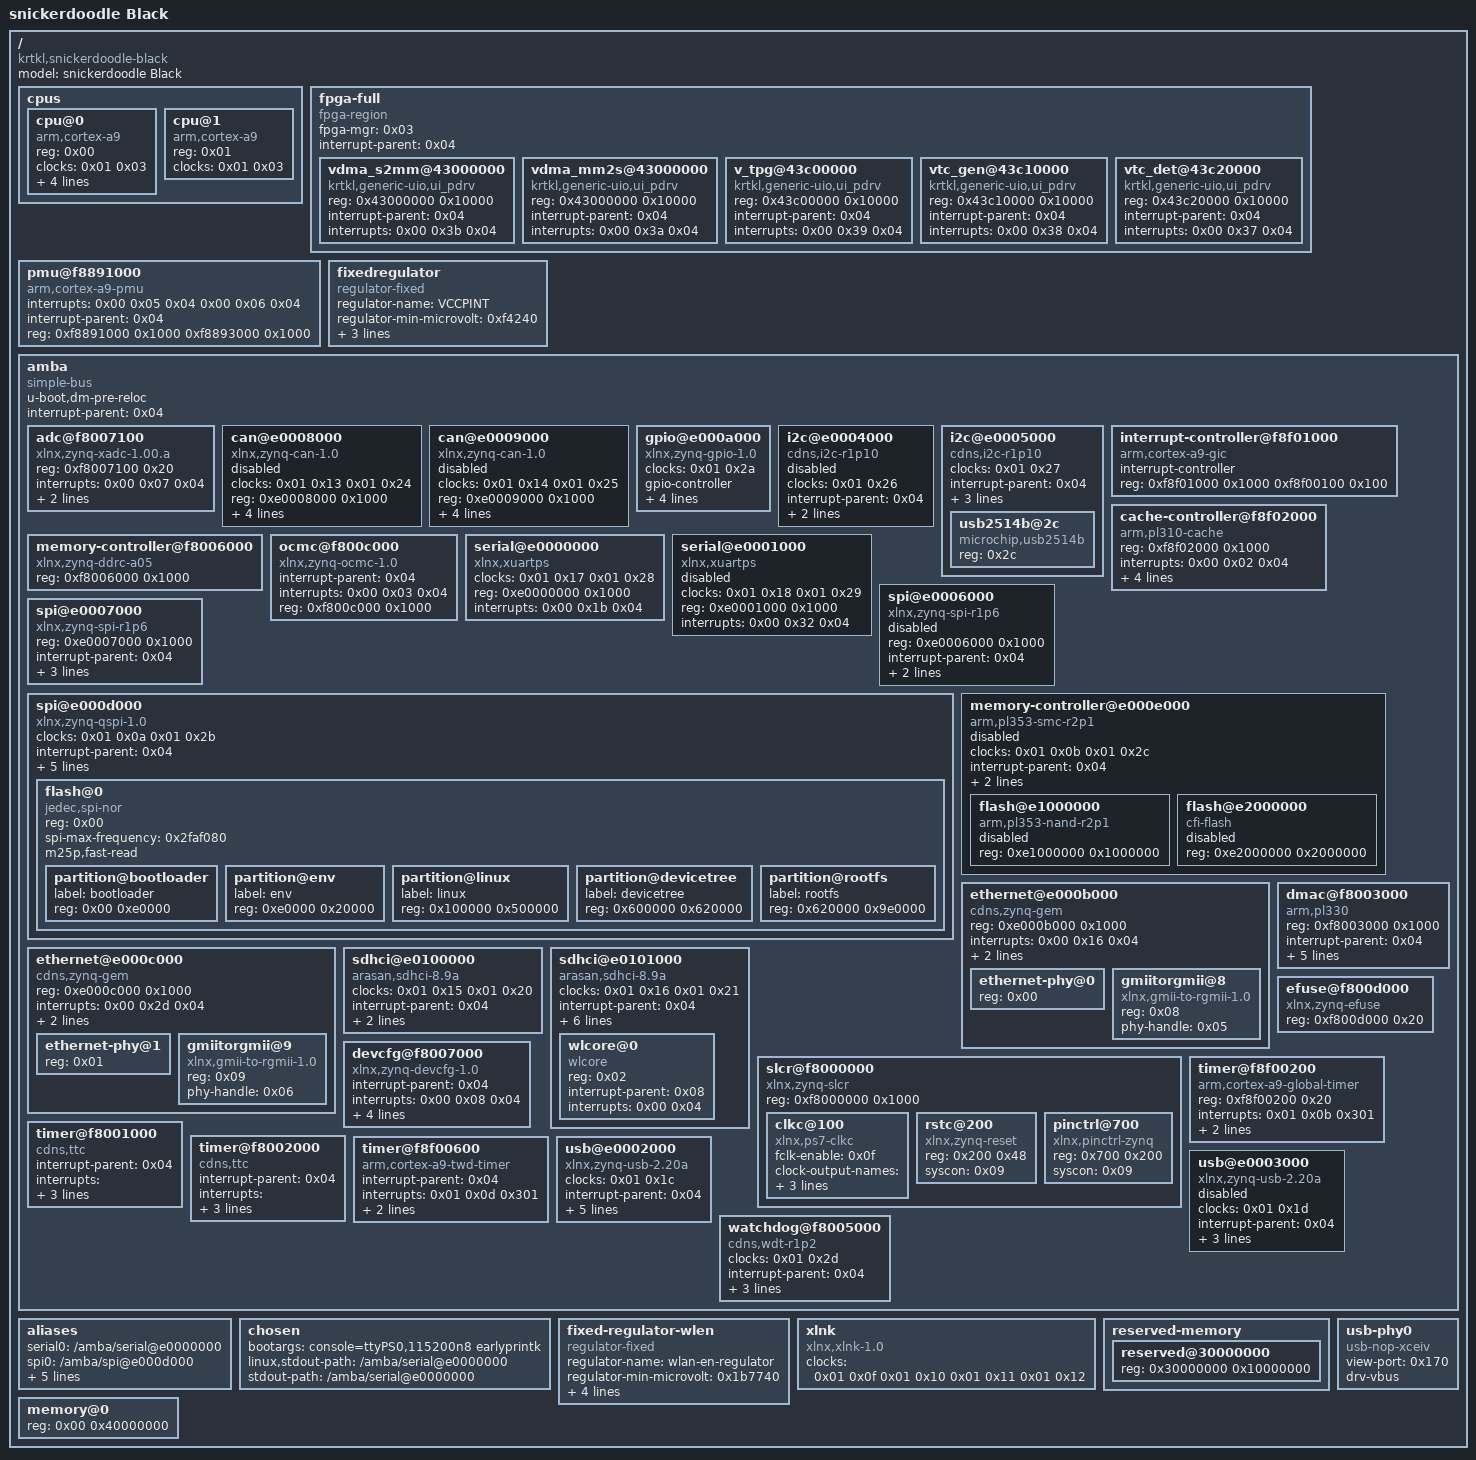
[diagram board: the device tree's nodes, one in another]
/dts-v1/;

/ {
	#address-cells = <0x01>;
	#size-cells = <0x01>;
	compatible = "krtkl,snickerdoodle-black\0krtkl,snickerdoodle\0xlnx,zynq-7000";
	model = "snickerdoodle Black";

	cpus {
		#address-cells = <0x01>;
		#size-cells = <0x00>;

		cpu@0 {
			compatible = "arm,cortex-a9";
			device_type = "cpu";
			reg = <0x00>;
			clocks = <0x01 0x03>;
			clock-latency = <0x3e8>;
			cpu0-supply = <0x02>;
			operating-points = <0xd396a 0xf4240 0x69cb5 0xf4240>;
			linux,phandle = <0x0b>;
			phandle = <0x0b>;
		};

		cpu@1 {
			compatible = "arm,cortex-a9";
			device_type = "cpu";
			reg = <0x01>;
			clocks = <0x01 0x03>;
			linux,phandle = <0x0c>;
			phandle = <0x0c>;
		};
	};

	fpga-full {
		compatible = "fpga-region";
		fpga-mgr = <0x03>;
		#address-cells = <0x01>;
		#size-cells = <0x01>;
		ranges;
		interrupt-parent = <0x04>;
		linux,phandle = <0x0d>;
		phandle = <0x0d>;

		vdma_s2mm@43000000 {
			compatible = "krtkl,generic-uio,ui_pdrv";
			reg = <0x43000000 0x10000>;
			status = "okay";
			interrupt-parent = <0x04>;
			interrupts = <0x00 0x3b 0x04>;
			linux,phandle = <0x0e>;
			phandle = <0x0e>;
		};

		vdma_mm2s@43000000 {
			compatible = "krtkl,generic-uio,ui_pdrv";
			reg = <0x43000000 0x10000>;
			status = "okay";
			interrupt-parent = <0x04>;
			interrupts = <0x00 0x3a 0x04>;
			linux,phandle = <0x0f>;
			phandle = <0x0f>;
		};

		v_tpg@43c00000 {
			reg = <0x43c00000 0x10000>;
			compatible = "krtkl,generic-uio,ui_pdrv";
			status = "okay";
			interrupt-parent = <0x04>;
			interrupts = <0x00 0x39 0x04>;
			linux,phandle = <0x10>;
			phandle = <0x10>;
		};

		vtc_gen@43c10000 {
			reg = <0x43c10000 0x10000>;
			compatible = "krtkl,generic-uio,ui_pdrv";
			status = "okay";
			interrupt-parent = <0x04>;
			interrupts = <0x00 0x38 0x04>;
			linux,phandle = <0x11>;
			phandle = <0x11>;
		};

		vtc_det@43c20000 {
			reg = <0x43c20000 0x10000>;
			compatible = "krtkl,generic-uio,ui_pdrv";
			status = "okay";
			interrupt-parent = <0x04>;
			interrupts = <0x00 0x37 0x04>;
			linux,phandle = <0x12>;
			phandle = <0x12>;
		};
	};

	pmu@f8891000 {
		compatible = "arm,cortex-a9-pmu";
		interrupts = <0x00 0x05 0x04 0x00 0x06 0x04>;
		interrupt-parent = <0x04>;
		reg = <0xf8891000 0x1000 0xf8893000 0x1000>;
	};

	fixedregulator {
		compatible = "regulator-fixed";
		regulator-name = "VCCPINT";
		regulator-min-microvolt = <0xf4240>;
		regulator-max-microvolt = <0xf4240>;
		regulator-boot-on;
		regulator-always-on;
		linux,phandle = <0x02>;
		phandle = <0x02>;
	};

	amba {
		u-boot,dm-pre-reloc;
		compatible = "simple-bus";
		#address-cells = <0x01>;
		#size-cells = <0x01>;
		interrupt-parent = <0x04>;
		ranges;
		linux,phandle = <0x13>;
		phandle = <0x13>;

		adc@f8007100 {
			compatible = "xlnx,zynq-xadc-1.00.a";
			reg = <0xf8007100 0x20>;
			interrupts = <0x00 0x07 0x04>;
			interrupt-parent = <0x04>;
			clocks = <0x01 0x0c>;
			linux,phandle = <0x14>;
			phandle = <0x14>;
		};

		can@e0008000 {
			compatible = "xlnx,zynq-can-1.0";
			status = "disabled";
			clocks = <0x01 0x13 0x01 0x24>;
			clock-names = "can_clk\0pclk";
			reg = <0xe0008000 0x1000>;
			interrupts = <0x00 0x1c 0x04>;
			interrupt-parent = <0x04>;
			tx-fifo-depth = <0x40>;
			rx-fifo-depth = <0x40>;
			linux,phandle = <0x15>;
			phandle = <0x15>;
		};

		can@e0009000 {
			compatible = "xlnx,zynq-can-1.0";
			status = "disabled";
			clocks = <0x01 0x14 0x01 0x25>;
			clock-names = "can_clk\0pclk";
			reg = <0xe0009000 0x1000>;
			interrupts = <0x00 0x33 0x04>;
			interrupt-parent = <0x04>;
			tx-fifo-depth = <0x40>;
			rx-fifo-depth = <0x40>;
			linux,phandle = <0x16>;
			phandle = <0x16>;
		};

		gpio@e000a000 {
			compatible = "xlnx,zynq-gpio-1.0";
			#gpio-cells = <0x02>;
			clocks = <0x01 0x2a>;
			gpio-controller;
			interrupt-controller;
			#interrupt-cells = <0x02>;
			interrupt-parent = <0x04>;
			interrupts = <0x00 0x14 0x04>;
			reg = <0xe000a000 0x1000>;
			linux,phandle = <0x08>;
			phandle = <0x08>;
		};

		i2c@e0004000 {
			compatible = "cdns,i2c-r1p10";
			status = "disabled";
			clocks = <0x01 0x26>;
			interrupt-parent = <0x04>;
			interrupts = <0x00 0x19 0x04>;
			reg = <0xe0004000 0x1000>;
			#address-cells = <0x01>;
			#size-cells = <0x00>;
			linux,phandle = <0x17>;
			phandle = <0x17>;
		};

		i2c@e0005000 {
			compatible = "cdns,i2c-r1p10";
			status = "okay";
			clocks = <0x01 0x27>;
			interrupt-parent = <0x04>;
			interrupts = <0x00 0x30 0x04>;
			reg = <0xe0005000 0x1000>;
			#address-cells = <0x01>;
			#size-cells = <0x00>;
			clock-frequency = <0x186a0>;
			linux,phandle = <0x18>;
			phandle = <0x18>;

			usb2514b@2c {
				compatible = "microchip,usb2514b";
				reg = <0x2c>;
			};
		};

		interrupt-controller@f8f01000 {
			compatible = "arm,cortex-a9-gic";
			#interrupt-cells = <0x03>;
			interrupt-controller;
			reg = <0xf8f01000 0x1000 0xf8f00100 0x100>;
			linux,phandle = <0x04>;
			phandle = <0x04>;
		};

		cache-controller@f8f02000 {
			compatible = "arm,pl310-cache";
			reg = <0xf8f02000 0x1000>;
			interrupts = <0x00 0x02 0x04>;
			arm,data-latency = <0x03 0x02 0x02>;
			arm,tag-latency = <0x02 0x02 0x02>;
			cache-unified;
			cache-level = <0x02>;
			linux,phandle = <0x19>;
			phandle = <0x19>;
		};

		memory-controller@f8006000 {
			compatible = "xlnx,zynq-ddrc-a05";
			reg = <0xf8006000 0x1000>;
			linux,phandle = <0x1a>;
			phandle = <0x1a>;
		};

		ocmc@f800c000 {
			compatible = "xlnx,zynq-ocmc-1.0";
			interrupt-parent = <0x04>;
			interrupts = <0x00 0x03 0x04>;
			reg = <0xf800c000 0x1000>;
			linux,phandle = <0x1b>;
			phandle = <0x1b>;
		};

		serial@e0000000 {
			compatible = "xlnx,xuartps\0cdns,uart-r1p8";
			status = "okay";
			clocks = <0x01 0x17 0x01 0x28>;
			clock-names = "uart_clk\0pclk";
			reg = <0xe0000000 0x1000>;
			interrupts = <0x00 0x1b 0x04>;
			linux,phandle = <0x1c>;
			phandle = <0x1c>;
		};

		serial@e0001000 {
			compatible = "xlnx,xuartps\0cdns,uart-r1p8";
			status = "disabled";
			clocks = <0x01 0x18 0x01 0x29>;
			clock-names = "uart_clk\0pclk";
			reg = <0xe0001000 0x1000>;
			interrupts = <0x00 0x32 0x04>;
			linux,phandle = <0x1d>;
			phandle = <0x1d>;
		};

		spi@e0006000 {
			compatible = "xlnx,zynq-spi-r1p6";
			reg = <0xe0006000 0x1000>;
			status = "disabled";
			interrupt-parent = <0x04>;
			interrupts = <0x00 0x1a 0x04>;
			clocks = <0x01 0x19 0x01 0x22>;
			clock-names = "ref_clk\0pclk";
			#address-cells = <0x01>;
			#size-cells = <0x00>;
			linux,phandle = <0x1e>;
			phandle = <0x1e>;
		};

		spi@e0007000 {
			compatible = "xlnx,zynq-spi-r1p6";
			reg = <0xe0007000 0x1000>;
			status = "okay";
			interrupt-parent = <0x04>;
			interrupts = <0x00 0x31 0x04>;
			clocks = <0x01 0x1a 0x01 0x23>;
			clock-names = "ref_clk\0pclk";
			#address-cells = <0x01>;
			#size-cells = <0x00>;
			num-cs = <0x01>;
			linux,phandle = <0x1f>;
			phandle = <0x1f>;
		};

		spi@e000d000 {
			clock-names = "ref_clk\0pclk";
			clocks = <0x01 0x0a 0x01 0x2b>;
			compatible = "xlnx,zynq-qspi-1.0";
			status = "okay";
			interrupt-parent = <0x04>;
			interrupts = <0x00 0x13 0x04>;
			reg = <0xe000d000 0x1000>;
			#address-cells = <0x01>;
			#size-cells = <0x00>;
			is-dual = <0x00>;
			num-cs = <0x01>;
			xlnx,qspi-mode = <0x01>;
			linux,phandle = <0x20>;
			phandle = <0x20>;

			flash@0 {
				#address-cells = <0x01>;
				#size-cells = <0x01>;
				compatible = "jedec,spi-nor";
				reg = <0x00>;
				spi-max-frequency = <0x2faf080>;
				m25p,fast-read;

				partition@bootloader {
					label = "bootloader";
					reg = <0x00 0xe0000>;
				};

				partition@env {
					label = "env";
					reg = <0xe0000 0x20000>;
				};

				partition@linux {
					label = "linux";
					reg = <0x100000 0x500000>;
				};

				partition@devicetree {
					label = "devicetree";
					reg = <0x600000 0x620000>;
				};

				partition@rootfs {
					label = "rootfs";
					reg = <0x620000 0x9e0000>;
				};
			};
		};

		memory-controller@e000e000 {
			#address-cells = <0x01>;
			#size-cells = <0x01>;
			status = "disabled";
			clock-names = "memclk\0aclk";
			clocks = <0x01 0x0b 0x01 0x2c>;
			compatible = "arm,pl353-smc-r2p1";
			interrupt-parent = <0x04>;
			interrupts = <0x00 0x12 0x04>;
			ranges;
			reg = <0xe000e000 0x1000>;
			linux,phandle = <0x21>;
			phandle = <0x21>;

			flash@e1000000 {
				status = "disabled";
				compatible = "arm,pl353-nand-r2p1";
				reg = <0xe1000000 0x1000000>;
				#address-cells = <0x01>;
				#size-cells = <0x01>;
				linux,phandle = <0x22>;
				phandle = <0x22>;
			};

			flash@e2000000 {
				status = "disabled";
				compatible = "cfi-flash";
				reg = <0xe2000000 0x2000000>;
				#address-cells = <0x01>;
				#size-cells = <0x01>;
				linux,phandle = <0x23>;
				phandle = <0x23>;
			};
		};

		ethernet@e000b000 {
			compatible = "cdns,zynq-gem\0cdns,gem";
			reg = <0xe000b000 0x1000>;
			status = "okay";
			interrupts = <0x00 0x16 0x04>;
			clocks = <0x01 0x1e 0x01 0x1e 0x01 0x0d>;
			clock-names = "pclk\0hclk\0tx_clk";
			#address-cells = <0x01>;
			#size-cells = <0x00>;
			phy-mode = "rgmii-id";
			linux,phandle = <0x24>;
			phandle = <0x24>;

			ethernet-phy@0 {
				reg = <0x00>;
				device_type = "ethernet-phy";
				linux,phandle = <0x05>;
				phandle = <0x05>;
			};

			gmiitorgmii@8 {
				compatible = "xlnx,gmii-to-rgmii-1.0";
				reg = <0x08>;
				phy-handle = <0x05>;
				linux,phandle = <0x25>;
				phandle = <0x25>;
			};
		};

		ethernet@e000c000 {
			compatible = "cdns,zynq-gem\0cdns,gem";
			reg = <0xe000c000 0x1000>;
			status = "okay";
			interrupts = <0x00 0x2d 0x04>;
			clocks = <0x01 0x1f 0x01 0x1f 0x01 0x0e>;
			clock-names = "pclk\0hclk\0tx_clk";
			#address-cells = <0x01>;
			#size-cells = <0x00>;
			phy-mode = "rgmii-id";
			linux,phandle = <0x26>;
			phandle = <0x26>;

			ethernet-phy@1 {
				reg = <0x01>;
				device_type = "ethernet-phy";
				linux,phandle = <0x06>;
				phandle = <0x06>;
			};

			gmiitorgmii@9 {
				compatible = "xlnx,gmii-to-rgmii-1.0";
				reg = <0x09>;
				phy-handle = <0x06>;
				linux,phandle = <0x27>;
				phandle = <0x27>;
			};
		};

		sdhci@e0100000 {
			compatible = "arasan,sdhci-8.9a";
			status = "okay";
			clock-names = "clk_xin\0clk_ahb";
			clocks = <0x01 0x15 0x01 0x20>;
			interrupt-parent = <0x04>;
			interrupts = <0x00 0x18 0x04>;
			reg = <0xe0100000 0x1000>;
			linux,phandle = <0x28>;
			phandle = <0x28>;
		};

		sdhci@e0101000 {
			compatible = "arasan,sdhci-8.9a";
			status = "okay";
			clock-names = "clk_xin\0clk_ahb";
			clocks = <0x01 0x16 0x01 0x21>;
			interrupt-parent = <0x04>;
			interrupts = <0x00 0x2f 0x04>;
			reg = <0xe0101000 0x1000>;
			vmmc-supply = <0x07>;
			bus-width = <0x04>;
			cap-power-off-card;
			keep-power-in-suspend;
			#address-cells = <0x01>;
			#size-cells = <0x00>;
			linux,phandle = <0x29>;
			phandle = <0x29>;

			wlcore@0 {
				reg = <0x02>;
				interrupt-parent = <0x08>;
				interrupts = <0x00 0x04>;
				compatible = "wlcore\0ti,wl1837";
				linux,phandle = <0x2a>;
				phandle = <0x2a>;
			};
		};

		slcr@f8000000 {
			#address-cells = <0x01>;
			#size-cells = <0x01>;
			compatible = "xlnx,zynq-slcr\0syscon\0simple-mfd";
			reg = <0xf8000000 0x1000>;
			ranges;
			linux,phandle = <0x09>;
			phandle = <0x09>;

			clkc@100 {
				#clock-cells = <0x01>;
				compatible = "xlnx,ps7-clkc";
				fclk-enable = <0x0f>;
				clock-output-names = "armpll\0ddrpll\0iopll\0cpu_6or4x\0cpu_3or2x\0cpu_2x\0cpu_1x\0ddr2x\0ddr3x\0dci\0lqspi\0smc\0pcap\0gem0\0gem1\0fclk0\0fclk1\0fclk2\0fclk3\0can0\0can1\0sdio0\0sdio1\0uart0\0uart1\0spi0\0spi1\0dma\0usb0_aper\0usb1_aper\0gem0_aper\0gem1_aper\0sdio0_aper\0sdio1_aper\0spi0_aper\0spi1_aper\0can0_aper\0can1_aper\0i2c0_aper\0i2c1_aper\0uart0_aper\0uart1_aper\0gpio_aper\0lqspi_aper\0smc_aper\0swdt\0dbg_trc\0dbg_apb";
				reg = <0x100 0x100>;
				ps-clk-frequency = <0x1fca055>;
				linux,phandle = <0x01>;
				phandle = <0x01>;
			};

			rstc@200 {
				compatible = "xlnx,zynq-reset";
				reg = <0x200 0x48>;
				#reset-cells = <0x01>;
				syscon = <0x09>;
				linux,phandle = <0x2b>;
				phandle = <0x2b>;
			};

			pinctrl@700 {
				compatible = "xlnx,pinctrl-zynq";
				reg = <0x700 0x200>;
				syscon = <0x09>;
				linux,phandle = <0x2c>;
				phandle = <0x2c>;
			};
		};

		dmac@f8003000 {
			compatible = "arm,pl330\0arm,primecell";
			reg = <0xf8003000 0x1000>;
			interrupt-parent = <0x04>;
			interrupt-names = "abort\0dma0\0dma1\0dma2\0dma3\0dma4\0dma5\0dma6\0dma7";
			interrupts = <0x00 0x0d 0x04 0x00 0x0e 0x04 0x00 0x0f 0x04 0x00 0x10 0x04 0x00 0x11 0x04 0x00 0x28 0x04 0x00 0x29 0x04 0x00 0x2a 0x04 0x00 0x2b 0x04>;
			#dma-cells = <0x01>;
			#dma-channels = <0x08>;
			#dma-requests = <0x04>;
			clocks = <0x01 0x1b>;
			clock-names = "apb_pclk";
			linux,phandle = <0x2d>;
			phandle = <0x2d>;
		};

		devcfg@f8007000 {
			compatible = "xlnx,zynq-devcfg-1.0";
			interrupt-parent = <0x04>;
			interrupts = <0x00 0x08 0x04>;
			reg = <0xf8007000 0x100>;
			clocks = <0x01 0x0c 0x01 0x0f 0x01 0x10 0x01 0x11 0x01 0x12>;
			clock-names = "ref_clk\0fclk0\0fclk1\0fclk2\0fclk3";
			syscon = <0x09>;
			linux,phandle = <0x03>;
			phandle = <0x03>;
		};

		efuse@f800d000 {
			compatible = "xlnx,zynq-efuse";
			reg = <0xf800d000 0x20>;
			linux,phandle = <0x2e>;
			phandle = <0x2e>;
		};

		timer@f8f00200 {
			compatible = "arm,cortex-a9-global-timer";
			reg = <0xf8f00200 0x20>;
			interrupts = <0x01 0x0b 0x301>;
			interrupt-parent = <0x04>;
			clocks = <0x01 0x04>;
			linux,phandle = <0x2f>;
			phandle = <0x2f>;
		};

		timer@f8001000 {
			interrupt-parent = <0x04>;
			interrupts = <0x00 0x0a 0x04 0x00 0x0b 0x04 0x00 0x0c 0x04>;
			compatible = "cdns,ttc";
			clocks = <0x01 0x06>;
			reg = <0xf8001000 0x1000>;
			linux,phandle = <0x30>;
			phandle = <0x30>;
		};

		timer@f8002000 {
			interrupt-parent = <0x04>;
			interrupts = <0x00 0x25 0x04 0x00 0x26 0x04 0x00 0x27 0x04>;
			compatible = "cdns,ttc";
			clocks = <0x01 0x06>;
			reg = <0xf8002000 0x1000>;
			linux,phandle = <0x31>;
			phandle = <0x31>;
		};

		timer@f8f00600 {
			interrupt-parent = <0x04>;
			interrupts = <0x01 0x0d 0x301>;
			compatible = "arm,cortex-a9-twd-timer";
			reg = <0xf8f00600 0x20>;
			clocks = <0x01 0x04>;
			linux,phandle = <0x32>;
			phandle = <0x32>;
		};

		usb@e0002000 {
			compatible = "xlnx,zynq-usb-2.20a\0chipidea,usb2";
			status = "okay";
			clocks = <0x01 0x1c>;
			interrupt-parent = <0x04>;
			interrupts = <0x00 0x15 0x04>;
			reg = <0xe0002000 0x1000>;
			phy_type = "ulpi";
			dr_mode = "host";
			usb-phy = <0x0a>;
			linux,phandle = <0x33>;
			phandle = <0x33>;
		};

		usb@e0003000 {
			compatible = "xlnx,zynq-usb-2.20a\0chipidea,usb2";
			status = "disabled";
			clocks = <0x01 0x1d>;
			interrupt-parent = <0x04>;
			interrupts = <0x00 0x2c 0x04>;
			reg = <0xe0003000 0x1000>;
			phy_type = "ulpi";
			linux,phandle = <0x34>;
			phandle = <0x34>;
		};

		watchdog@f8005000 {
			clocks = <0x01 0x2d>;
			compatible = "cdns,wdt-r1p2";
			interrupt-parent = <0x04>;
			interrupts = <0x00 0x09 0x01>;
			reg = <0xf8005000 0x1000>;
			timeout-sec = <0x0a>;
			linux,phandle = <0x35>;
			phandle = <0x35>;
		};
	};

	aliases {
		serial0 = "/amba/serial@e0000000";
		spi0 = "/amba/spi@e000d000";
		spi1 = "/amba/spi@e0007000";
		mmc0 = "/amba/sdhci@e0100000";
		mmc1 = "/amba/sdhci@e0101000";
		ethernet0 = "/amba/ethernet@e000b000";
		ethernet1 = "/amba/ethernet@e000c000";
	};

	chosen {
		bootargs = "console=ttyPS0,115200n8 earlyprintk";
		linux,stdout-path = "/amba/serial@e0000000";
		stdout-path = "/amba/serial@e0000000";
	};

	fixed-regulator-wlen {
		compatible = "regulator-fixed";
		regulator-name = "wlan-en-regulator";
		regulator-min-microvolt = <0x1b7740>;
		regulator-max-microvolt = <0x1b7740>;
		gpio = <0x08 0x09 0x04>;
		startup-delay-us = <0x11170>;
		enable-active-high;
		linux,phandle = <0x07>;
		phandle = <0x07>;
	};

	xlnk {
		compatible = "xlnx,xlnk-1.0";
		clock-names = "clk50\0clk100\0clk150\0clk200";
		clocks = <0x01 0x0f 0x01 0x10 0x01 0x11 0x01 0x12>;
	};

	reserved-memory {
		#address-cells = <0x01>;
		#size-cells = <0x01>;
		ranges;

		reserved@30000000 {
			reg = <0x30000000 0x10000000>;
		};
	};

	memory@0 {
		device_type = "memory";
		reg = <0x00 0x40000000>;
	};

	usb-phy0 {
		compatible = "usb-nop-xceiv";
		#phy-cells = <0x00>;
		view-port = <0x170>;
		drv-vbus;
		linux,phandle = <0x0a>;
		phandle = <0x0a>;
	};

	__symbols__ {
		cpu0 = "/cpus/cpu@0";
		cpu1 = "/cpus/cpu@1";
		fpga_full = "/fpga-full";
		uio0 = "/fpga-full/vdma_s2mm@43000000";
		uio1 = "/fpga-full/vdma_mm2s@43000000";
		uio2 = "/fpga-full/v_tpg@43c00000";
		uio3 = "/fpga-full/vtc_gen@43c10000";
		uio4 = "/fpga-full/vtc_det@43c20000";
		regulator_vccpint = "/fixedregulator";
		amba = "/amba";
		adc = "/amba/adc@f8007100";
		can0 = "/amba/can@e0008000";
		can1 = "/amba/can@e0009000";
		gpio0 = "/amba/gpio@e000a000";
		i2c0 = "/amba/i2c@e0004000";
		i2c1 = "/amba/i2c@e0005000";
		intc = "/amba/interrupt-controller@f8f01000";
		L2 = "/amba/cache-controller@f8f02000";
		mc = "/amba/memory-controller@f8006000";
		ocmc = "/amba/ocmc@f800c000";
		uart0 = "/amba/serial@e0000000";
		uart1 = "/amba/serial@e0001000";
		spi0 = "/amba/spi@e0006000";
		spi1 = "/amba/spi@e0007000";
		qspi = "/amba/spi@e000d000";
		smcc = "/amba/memory-controller@e000e000";
		nand0 = "/amba/memory-controller@e000e000/flash@e1000000";
		nor0 = "/amba/memory-controller@e000e000/flash@e2000000";
		gem0 = "/amba/ethernet@e000b000";
		eth_phy0 = "/amba/ethernet@e000b000/ethernet-phy@0";
		gmii2rgmii0 = "/amba/ethernet@e000b000/gmiitorgmii@8";
		gem1 = "/amba/ethernet@e000c000";
		eth_phy1 = "/amba/ethernet@e000c000/ethernet-phy@1";
		gmii2rgmii1 = "/amba/ethernet@e000c000/gmiitorgmii@9";
		sdhci0 = "/amba/sdhci@e0100000";
		sdhci1 = "/amba/sdhci@e0101000";
		wlcore = "/amba/sdhci@e0101000/wlcore@0";
		slcr = "/amba/slcr@f8000000";
		clkc = "/amba/slcr@f8000000/clkc@100";
		rstc = "/amba/slcr@f8000000/rstc@200";
		pinctrl0 = "/amba/slcr@f8000000/pinctrl@700";
		dmac_s = "/amba/dmac@f8003000";
		devcfg = "/amba/devcfg@f8007000";
		efuse = "/amba/efuse@f800d000";
		global_timer = "/amba/timer@f8f00200";
		ttc0 = "/amba/timer@f8001000";
		ttc1 = "/amba/timer@f8002000";
		scutimer = "/amba/timer@f8f00600";
		usb0 = "/amba/usb@e0002000";
		usb1 = "/amba/usb@e0003000";
		watchdog0 = "/amba/watchdog@f8005000";
		wlan_en_reg = "/fixed-regulator-wlen";
		usb_phy0 = "/usb-phy0";
	};
};
